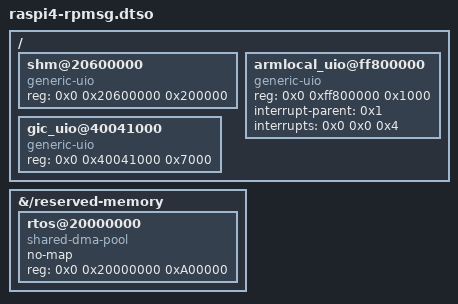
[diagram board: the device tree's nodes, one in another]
/dts-v1/;
/plugin/;
/ {
    fragment@0 {
        target-path="/reserved-memory";
        __overlay__ {
            rtos@20000000 {
                compatible = "shared-dma-pool";
                no-map;
                reg = <0x0 0x20000000 0xA00000>;
            };
        };
    };

    fragment@1 {
        target-path="/";
        __overlay__ {
            shm@20600000 {
                compatible = "generic-uio";
                status = "okay";
                reg = <0x0 0x20600000 0x200000>;
            };

            armlocal_uio@ff800000 {
                compatible = "generic-uio";
                status = "okay";
                reg = <0x0 0xff800000 0x1000>;
                interrupt-parent = <0x1>;
                interrupts = <0x0 0x0 0x4>;
            };

            gic_uio@40041000 {
                compatible = "generic-uio";
                status = "okay";
                reg = <0x0 0x40041000 0x7000>;
            };
        };
    };
};
